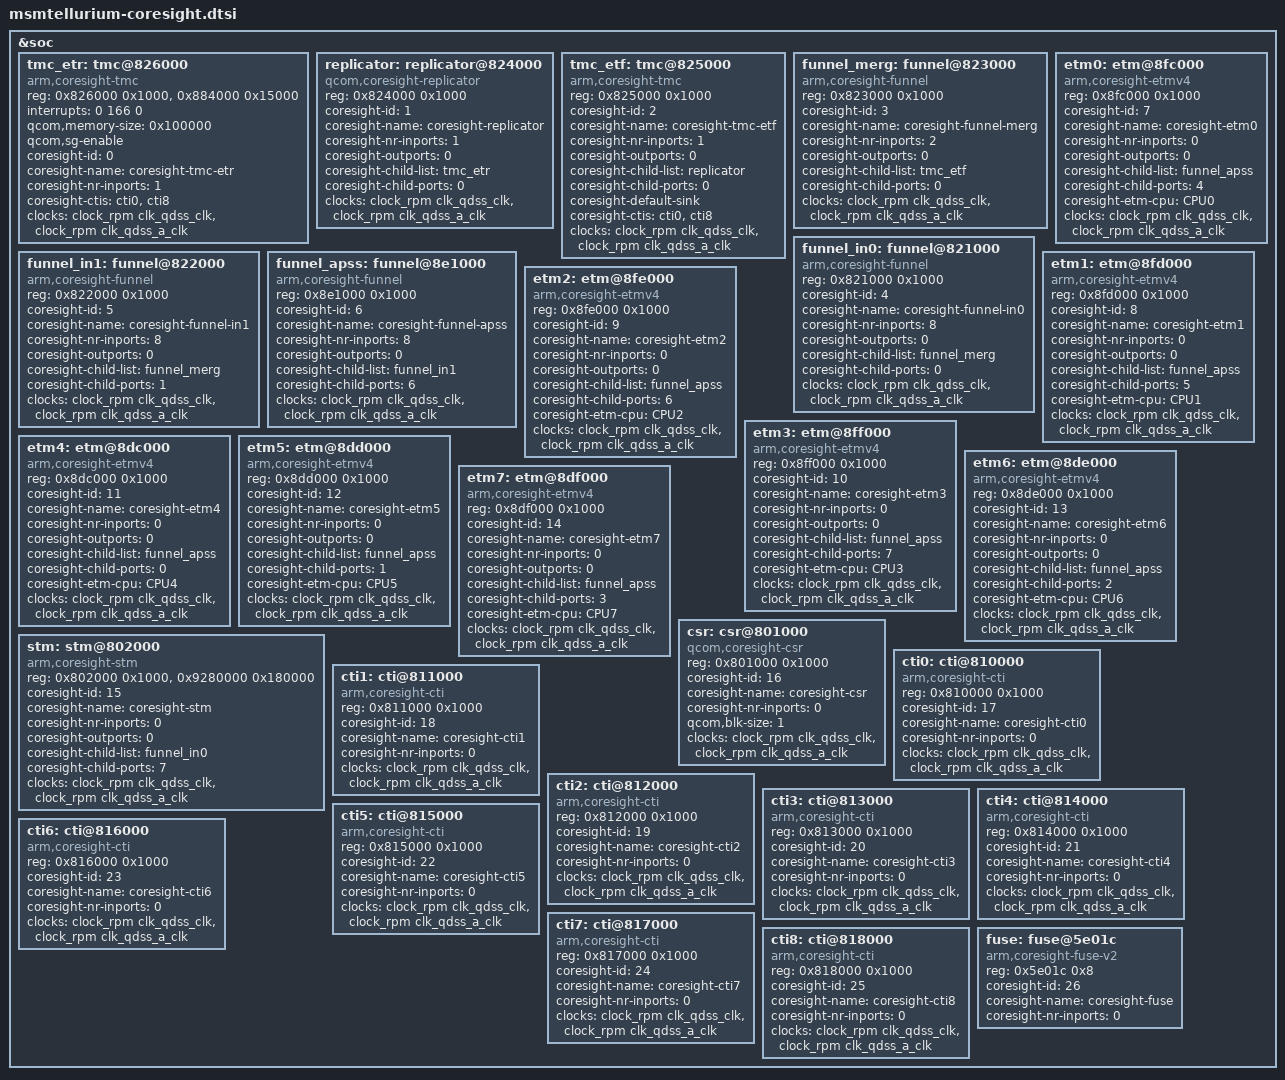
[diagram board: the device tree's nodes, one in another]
/* Copyright (c) 2014, The Linux Foundation. All rights reserved.
 *
 * This program is free software; you can redistribute it and/or modify
 * it under the terms of the GNU General Public License version 2 and
 * only version 2 as published by the Free Software Foundation.
 *
 * This program is distributed in the hope that it will be useful,
 * but WITHOUT ANY WARRANTY; without even the implied warranty of
 * MERCHANTABILITY or FITNESS FOR A PARTICULAR PURPOSE.  See the
 * GNU General Public License for more details.
 */

&soc {
	tmc_etr: tmc@826000 {
		compatible = "arm,coresight-tmc";
		reg = <0x826000 0x1000>,
		      <0x884000 0x15000>;
		reg-names = "tmc-base", "bam-base";
		interrupts = <0 166 0>;
		interrupt-names = "byte-cntr-irq";

		qcom,memory-size = <0x100000>;
		qcom,sg-enable;

		coresight-id = <0>;
		coresight-name = "coresight-tmc-etr";
		coresight-nr-inports = <1>;
		coresight-ctis = <&cti0 &cti8>;

		clocks = <&clock_rpm clk_qdss_clk>,
			 <&clock_rpm clk_qdss_a_clk>;
		clock-names = "core_clk", "core_a_clk";
	};

	replicator: replicator@824000 {
		compatible = "qcom,coresight-replicator";
		reg = <0x824000 0x1000>;
		reg-names = "replicator-base";

		coresight-id = <1>;
		coresight-name = "coresight-replicator";
		coresight-nr-inports = <1>;
		coresight-outports = <0>;
		coresight-child-list = <&tmc_etr>;
		coresight-child-ports = <0>;

		clocks = <&clock_rpm clk_qdss_clk>,
			 <&clock_rpm clk_qdss_a_clk>;
		clock-names = "core_clk", "core_a_clk";
	};

	tmc_etf: tmc@825000 {
		compatible = "arm,coresight-tmc";
		reg = <0x825000 0x1000>;
		reg-names = "tmc-base";

		coresight-id = <2>;
		coresight-name = "coresight-tmc-etf";
		coresight-nr-inports = <1>;
		coresight-outports = <0>;
		coresight-child-list = <&replicator>;
		coresight-child-ports = <0>;
		coresight-default-sink;
		coresight-ctis = <&cti0 &cti8>;

		clocks = <&clock_rpm clk_qdss_clk>,
			 <&clock_rpm clk_qdss_a_clk>;
		clock-names = "core_clk", "core_a_clk";
	};

	funnel_merg: funnel@823000 {
		compatible = "arm,coresight-funnel";
		reg = <0x823000 0x1000>;
		reg-names = "funnel-base";

		coresight-id = <3>;
		coresight-name = "coresight-funnel-merg";
		coresight-nr-inports = <2>;
		coresight-outports = <0>;
		coresight-child-list = <&tmc_etf>;
		coresight-child-ports = <0>;

		clocks = <&clock_rpm clk_qdss_clk>,
			 <&clock_rpm clk_qdss_a_clk>;
		clock-names = "core_clk", "core_a_clk";
	};

	funnel_in0: funnel@821000 {
		compatible = "arm,coresight-funnel";
		reg = <0x821000 0x1000>;
		reg-names = "funnel-base";

		coresight-id = <4>;
		coresight-name = "coresight-funnel-in0";
		coresight-nr-inports = <8>;
		coresight-outports = <0>;
		coresight-child-list = <&funnel_merg>;
		coresight-child-ports = <0>;

		clocks = <&clock_rpm clk_qdss_clk>,
			 <&clock_rpm clk_qdss_a_clk>;
		clock-names = "core_clk", "core_a_clk";
	};

	funnel_in1: funnel@822000 {
		compatible = "arm,coresight-funnel";
		reg = <0x822000 0x1000>;
		reg-names = "funnel-base";

		coresight-id = <5>;
		coresight-name = "coresight-funnel-in1";
		coresight-nr-inports = <8>;
		coresight-outports = <0>;
		coresight-child-list = <&funnel_merg>;
		coresight-child-ports = <1>;

		clocks = <&clock_rpm clk_qdss_clk>,
			 <&clock_rpm clk_qdss_a_clk>;
		clock-names = "core_clk", "core_a_clk";
	};

	funnel_apss: funnel@8e1000 {
		compatible = "arm,coresight-funnel";
		reg = <0x8e1000 0x1000>;
		reg-names = "funnel-base";

		coresight-id = <6>;
		coresight-name = "coresight-funnel-apss";
		coresight-nr-inports = <8>;
		coresight-outports = <0>;
		coresight-child-list = <&funnel_in1>;
		coresight-child-ports = <6>;

		clocks = <&clock_rpm clk_qdss_clk>,
			 <&clock_rpm clk_qdss_a_clk>;
		clock-names = "core_clk", "core_a_clk";
	};

	etm0: etm@8fc000 {
		compatible = "arm,coresight-etmv4";
		reg = <0x8fc000 0x1000>;
		reg-names = "etm-base";

		coresight-id = <7>;
		coresight-name = "coresight-etm0";
		coresight-nr-inports = <0>;
		coresight-outports = <0>;
		coresight-child-list = <&funnel_apss>;
		coresight-child-ports = <4>;
		coresight-etm-cpu = <&CPU0>;

		clocks = <&clock_rpm clk_qdss_clk>,
			 <&clock_rpm clk_qdss_a_clk>;
		clock-names = "core_clk", "core_a_clk";
	};

	etm1: etm@8fd000 {
		compatible = "arm,coresight-etmv4";
		reg = <0x8fd000 0x1000>;
		reg-names = "etm-base";

		coresight-id = <8>;
		coresight-name = "coresight-etm1";
		coresight-nr-inports = <0>;
		coresight-outports = <0>;
		coresight-child-list = <&funnel_apss>;
		coresight-child-ports = <5>;
		coresight-etm-cpu = <&CPU1>;

		clocks = <&clock_rpm clk_qdss_clk>,
			 <&clock_rpm clk_qdss_a_clk>;
		clock-names = "core_clk", "core_a_clk";
	};

	etm2: etm@8fe000 {
		compatible = "arm,coresight-etmv4";
		reg = <0x8fe000 0x1000>;
		reg-names = "etm-base";

		coresight-id = <9>;
		coresight-name = "coresight-etm2";
		coresight-nr-inports = <0>;
		coresight-outports = <0>;
		coresight-child-list = <&funnel_apss>;
		coresight-child-ports = <6>;
		coresight-etm-cpu = <&CPU2>;

		clocks = <&clock_rpm clk_qdss_clk>,
			 <&clock_rpm clk_qdss_a_clk>;
		clock-names = "core_clk", "core_a_clk";
	};

	etm3: etm@8ff000 {
		compatible = "arm,coresight-etmv4";
		reg = <0x8ff000 0x1000>;
		reg-names = "etm-base";

		coresight-id = <10>;
		coresight-name = "coresight-etm3";
		coresight-nr-inports = <0>;
		coresight-outports = <0>;
		coresight-child-list = <&funnel_apss>;
		coresight-child-ports = <7>;
		coresight-etm-cpu = <&CPU3>;

		clocks = <&clock_rpm clk_qdss_clk>,
			 <&clock_rpm clk_qdss_a_clk>;
		clock-names = "core_clk", "core_a_clk";
	};

	etm4: etm@8dc000 {
		compatible = "arm,coresight-etmv4";
		reg = <0x8dc000 0x1000>;
		reg-names = "etm-base";

		coresight-id = <11>;
		coresight-name = "coresight-etm4";
		coresight-nr-inports = <0>;
		coresight-outports = <0>;
		coresight-child-list = <&funnel_apss>;
		coresight-child-ports = <0>;
		coresight-etm-cpu = <&CPU4>;

		clocks = <&clock_rpm clk_qdss_clk>,
			 <&clock_rpm clk_qdss_a_clk>;
		clock-names = "core_clk", "core_a_clk";
	};

	etm5: etm@8dd000 {
		compatible = "arm,coresight-etmv4";
		reg = <0x8dd000 0x1000>;
		reg-names = "etm-base";

		coresight-id = <12>;
		coresight-name = "coresight-etm5";
		coresight-nr-inports = <0>;
		coresight-outports = <0>;
		coresight-child-list = <&funnel_apss>;
		coresight-child-ports = <1>;
		coresight-etm-cpu = <&CPU5>;

		clocks = <&clock_rpm clk_qdss_clk>,
			 <&clock_rpm clk_qdss_a_clk>;
		clock-names = "core_clk", "core_a_clk";
	};

	etm6: etm@8de000 {
		compatible = "arm,coresight-etmv4";
		reg = <0x8de000 0x1000>;
		reg-names = "etm-base";

		coresight-id = <13>;
		coresight-name = "coresight-etm6";
		coresight-nr-inports = <0>;
		coresight-outports = <0>;
		coresight-child-list = <&funnel_apss>;
		coresight-child-ports = <2>;
		coresight-etm-cpu = <&CPU6>;

		clocks = <&clock_rpm clk_qdss_clk>,
			 <&clock_rpm clk_qdss_a_clk>;
		clock-names = "core_clk", "core_a_clk";
	};

	etm7: etm@8df000 {
		compatible = "arm,coresight-etmv4";
		reg = <0x8df000 0x1000>;
		reg-names = "etm-base";

		coresight-id = <14>;
		coresight-name = "coresight-etm7";
		coresight-nr-inports = <0>;
		coresight-outports = <0>;
		coresight-child-list = <&funnel_apss>;
		coresight-child-ports = <3>;
		coresight-etm-cpu = <&CPU7>;

		clocks = <&clock_rpm clk_qdss_clk>,
			 <&clock_rpm clk_qdss_a_clk>;
		clock-names = "core_clk", "core_a_clk";
	};

	stm: stm@802000 {
		compatible = "arm,coresight-stm";
		reg = <0x802000 0x1000>,
		      <0x9280000 0x180000>;
		reg-names = "stm-base", "stm-data-base";

		coresight-id = <15>;
		coresight-name = "coresight-stm";
		coresight-nr-inports = <0>;
		coresight-outports = <0>;
		coresight-child-list = <&funnel_in0>;
		coresight-child-ports = <7>;

		clocks = <&clock_rpm clk_qdss_clk>,
			 <&clock_rpm clk_qdss_a_clk>;
		clock-names = "core_clk", "core_a_clk";
	};

	csr: csr@801000 {
		compatible = "qcom,coresight-csr";
		reg = <0x801000 0x1000>;
		reg-names = "csr-base";

		coresight-id = <16>;
		coresight-name = "coresight-csr";
		coresight-nr-inports = <0>;
		qcom,blk-size = <1>;

		clocks = <&clock_rpm clk_qdss_clk>,
			 <&clock_rpm clk_qdss_a_clk>;
		clock-names = "core_clk", "core_a_clk";
	};

	cti0: cti@810000 {
		compatible = "arm,coresight-cti";
		reg = <0x810000 0x1000>;
		reg-names = "cti-base";

		coresight-id = <17>;
		coresight-name = "coresight-cti0";
		coresight-nr-inports = <0>;

		clocks = <&clock_rpm clk_qdss_clk>,
			 <&clock_rpm clk_qdss_a_clk>;
		clock-names = "core_clk", "core_a_clk";
	};

	cti1: cti@811000 {
		compatible = "arm,coresight-cti";
		reg = <0x811000 0x1000>;
		reg-names = "cti-base";

		coresight-id = <18>;
		coresight-name = "coresight-cti1";
		coresight-nr-inports = <0>;

		clocks = <&clock_rpm clk_qdss_clk>,
			 <&clock_rpm clk_qdss_a_clk>;
		clock-names = "core_clk", "core_a_clk";
	};

	cti2: cti@812000 {
		compatible = "arm,coresight-cti";
		reg = <0x812000 0x1000>;
		reg-names = "cti-base";

		coresight-id = <19>;
		coresight-name = "coresight-cti2";
		coresight-nr-inports = <0>;

		clocks = <&clock_rpm clk_qdss_clk>,
			 <&clock_rpm clk_qdss_a_clk>;
		clock-names = "core_clk", "core_a_clk";
	};

	cti3: cti@813000 {
		compatible = "arm,coresight-cti";
		reg = <0x813000 0x1000>;
		reg-names = "cti-base";

		coresight-id = <20>;
		coresight-name = "coresight-cti3";
		coresight-nr-inports = <0>;

		clocks = <&clock_rpm clk_qdss_clk>,
			 <&clock_rpm clk_qdss_a_clk>;
		clock-names = "core_clk", "core_a_clk";
	};

	cti4: cti@814000 {
		compatible = "arm,coresight-cti";
		reg = <0x814000 0x1000>;
		reg-names = "cti-base";

		coresight-id = <21>;
		coresight-name = "coresight-cti4";
		coresight-nr-inports = <0>;

		clocks = <&clock_rpm clk_qdss_clk>,
			 <&clock_rpm clk_qdss_a_clk>;
		clock-names = "core_clk", "core_a_clk";
	};

	cti5: cti@815000 {
		compatible = "arm,coresight-cti";
		reg = <0x815000 0x1000>;
		reg-names = "cti-base";

		coresight-id = <22>;
		coresight-name = "coresight-cti5";
		coresight-nr-inports = <0>;

		clocks = <&clock_rpm clk_qdss_clk>,
			 <&clock_rpm clk_qdss_a_clk>;
		clock-names = "core_clk", "core_a_clk";
	};

	cti6: cti@816000 {
		compatible = "arm,coresight-cti";
		reg = <0x816000 0x1000>;
		reg-names = "cti-base";

		coresight-id = <23>;
		coresight-name = "coresight-cti6";
		coresight-nr-inports = <0>;

		clocks = <&clock_rpm clk_qdss_clk>,
			 <&clock_rpm clk_qdss_a_clk>;
		clock-names = "core_clk", "core_a_clk";
	};

	cti7: cti@817000 {
		compatible = "arm,coresight-cti";
		reg = <0x817000 0x1000>;
		reg-names = "cti-base";

		coresight-id = <24>;
		coresight-name = "coresight-cti7";
		coresight-nr-inports = <0>;

		clocks = <&clock_rpm clk_qdss_clk>,
			 <&clock_rpm clk_qdss_a_clk>;
		clock-names = "core_clk", "core_a_clk";
	};

	cti8: cti@818000 {
		compatible = "arm,coresight-cti";
		reg = <0x818000 0x1000>;
		reg-names = "cti-base";

		coresight-id = <25>;
		coresight-name = "coresight-cti8";
		coresight-nr-inports = <0>;

		clocks = <&clock_rpm clk_qdss_clk>,
			 <&clock_rpm clk_qdss_a_clk>;
		clock-names = "core_clk", "core_a_clk";
	};

	fuse: fuse@5e01c {
		compatible = "arm,coresight-fuse-v2";
		reg = <0x5e01c 0x8>;
		reg-names = "fuse-base";

		coresight-id = <26>;
		coresight-name = "coresight-fuse";
		coresight-nr-inports = <0>;
	};
};
